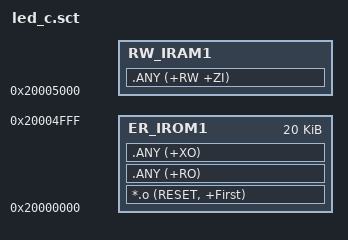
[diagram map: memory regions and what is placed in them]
; *************************************************************
; *** Scatter-Loading Description File generated by uVision ***
; *************************************************************

LR_IROM1 0x20000000 0x5000  {    ; load region size_region 0x08009000  0x20000
  ER_IROM1 0x20000000 0x5000  {  ; load address = execution address0x20000000 0x10000
   *.o (RESET, +First)
   .ANY (+RO)
   .ANY (+XO)
  }
  RW_IRAM1 0x20005000 {	
   .ANY (+RW +ZI)
}

}

